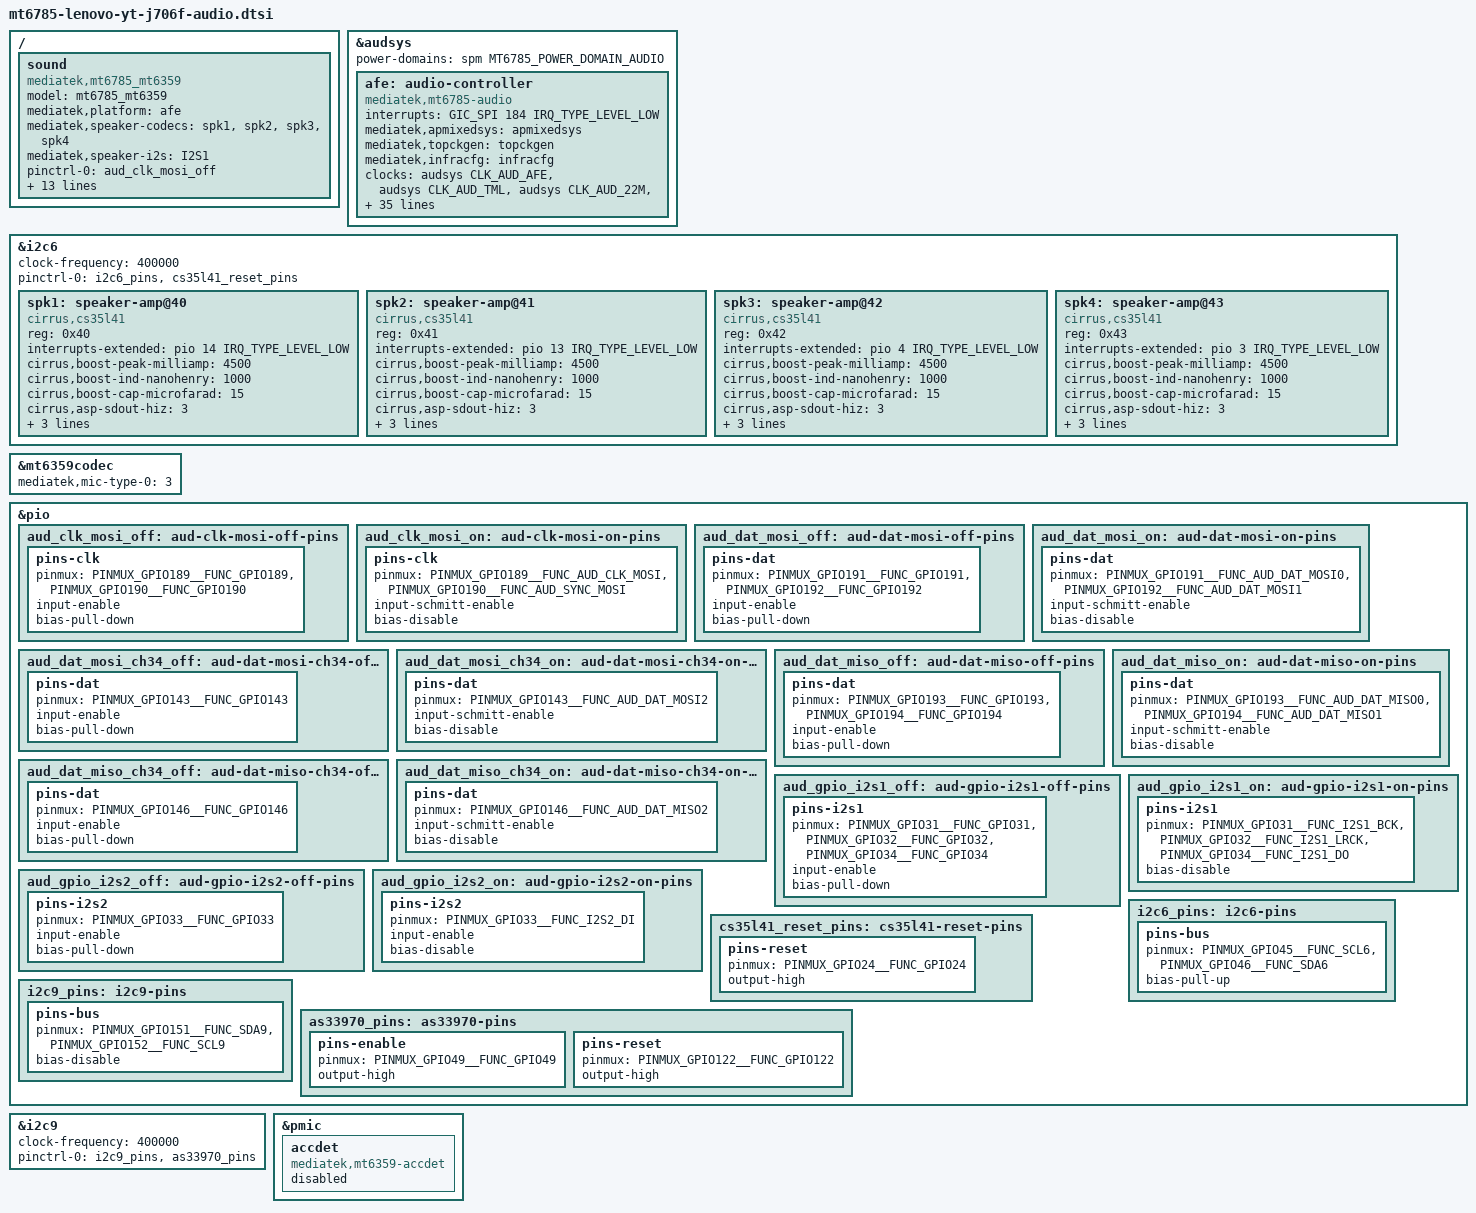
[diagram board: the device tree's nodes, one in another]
// SPDX-License-Identifier: (GPL-2.0 OR MIT)
/*
 * Audio device tree for the Lenovo Yoga Tab 11 (YT-J706F, MediaTek MT6785):
 * AFE, MT6359 PMIC codec, sound card, and 4x Cirrus Logic CS35L41
 * speaker amplifiers on i2c6.
 */

#include <dt-bindings/clock/mediatek,mt6785-clk.h>
#include <dt-bindings/interrupt-controller/arm-gic.h>
#include <dt-bindings/interrupt-controller/irq.h>
#include <dt-bindings/pinctrl/mediatek,mt6785-pinfunc.h>
#include <dt-bindings/power/mediatek,mt6785-power.h>

/*
 * AFE and its clocks adapted from Xiaomi begonia (same MT6785 SoC):
 * clock-names match aud_clks[] in mt6785-afe-clk.c (plus aud_tdm_clk for
 * mt6785-dai-tdm.c); top_i2s6..9 / apll12_div6..9 do not exist on MT6785 and
 * are treated as optional by the driver.
 */
&audsys {
	power-domains = <&spm MT6785_POWER_DOMAIN_AUDIO>;

	afe: audio-controller {
		compatible = "mediatek,mt6785-audio";
		interrupts = <GIC_SPI 184 IRQ_TYPE_LEVEL_LOW>;

		mediatek,apmixedsys = <&apmixedsys>;
		mediatek,topckgen = <&topckgen>;
		mediatek,infracfg = <&infracfg>;

		clocks = <&audsys CLK_AUD_AFE>,
			 <&audsys CLK_AUD_TML>,
			 <&audsys CLK_AUD_22M>,
			 <&audsys CLK_AUD_24M>,
			 <&audsys CLK_AUD_APLL_TUNER>,
			 <&audsys CLK_AUD_APLL2_TUNER>,
			 <&audsys CLK_AUD_TDM>,
			 <&audsys CLK_AUD_NLE>,
			 <&infracfg CLK_INFRA_AUDIO>,
			 <&infracfg CLK_INFRA_AUDIO_26M>,
			 <&topckgen CLK_TOP_AUDIO>,
			 <&topckgen CLK_TOP_AUDIO_INTBUS>,
			 <&topckgen CLK_TOP_AUDIO1>,
			 <&apmixedsys CLK_APMIXED_APLL1>,
			 <&topckgen CLK_TOP_AUDIO2>,
			 <&apmixedsys CLK_APMIXED_APLL2>,
			 <&topckgen CLK_TOP_AUDIO_ENG1>,
			 <&topckgen CLK_TOP_APLL1_D8>,
			 <&topckgen CLK_TOP_AUDIO_ENG2>,
			 <&topckgen CLK_TOP_APLL2_D8>,
			 <&topckgen CLK_TOP_AUDIO_HIRES>,
			 <&topckgen CLK_TOP_APLL_I2S0>,
			 <&topckgen CLK_TOP_APLL_I2S1>,
			 <&topckgen CLK_TOP_APLL_I2S2>,
			 <&topckgen CLK_TOP_APLL_I2S3>,
			 <&topckgen CLK_TOP_APLL_I2S4>,
			 <&topckgen CLK_TOP_APLL_I2S5>,
			 <&topckgen CLK_TOP_APLL12_DIV0>,
			 <&topckgen CLK_TOP_APLL12_DIV1>,
			 <&topckgen CLK_TOP_APLL12_DIV2>,
			 <&topckgen CLK_TOP_APLL12_DIV3>,
			 <&topckgen CLK_TOP_APLL12_DIV4>,
			 <&topckgen CLK_TOP_APLL12_DIVB>,
			 <&topckgen CLK_TOP_APLL12_DIV5>,
			 <&clk26m>,
			 /* ADDA DAPM clock supplies needed for DAC/ADC routes */
			 <&audsys CLK_AUD_DAC>,
			 <&audsys CLK_AUD_DAC_PREDIS>,
			 <&audsys CLK_AUD_3RD_DAC>,
			 <&audsys CLK_AUD_3RD_DAC_PREDIS>,
			 <&audsys CLK_AUD_ADC>,
			 <&audsys CLK_AUD_ADDA6_ADC>;
		clock-names = "aud_afe_clk",
			      "aud_tml_clk",
			      "aud_apll22m_clk",
			      "aud_apll24m_clk",
			      "aud_apll1_tuner_clk",
			      "aud_apll2_tuner_clk",
			      "aud_tdm_clk",
			      "aud_nle",
			      "aud_infra_clk",
			      "aud_infra_26m_clk",
			      "top_mux_audio",
			      "top_mux_audio_int",
			      "top_mux_aud_1",
			      "top_apll1_ck",
			      "top_mux_aud_2",
			      "top_apll2_ck",
			      "top_mux_aud_eng1",
			      "top_apll1_d8",
			      "top_mux_aud_eng2",
			      "top_apll2_d8",
			      "top_mux_audio_h",
			      "top_i2s0_m_sel",
			      "top_i2s1_m_sel",
			      "top_i2s2_m_sel",
			      "top_i2s3_m_sel",
			      "top_i2s4_m_sel",
			      "top_i2s5_m_sel",
			      "top_apll12_div0",
			      "top_apll12_div1",
			      "top_apll12_div2",
			      "top_apll12_div3",
			      "top_apll12_div4",
			      "top_apll12_divb",
			      "top_apll12_div5",
			      "top_clk26m_clk",
			      "aud_dac_clk",
			      "aud_dac_predis_clk",
			      "aud_3rd_dac_clk",
			      "aud_3rd_dac_predis_clk",
			      "aud_adc_clk",
			      "aud_adda6_adc_clk";
	};
};

/*
 * 4x Cirrus Logic CS35L41 speaker amplifiers on i2c6 (stock DT / hardware):
 * all four share active-low reset GPIO24; mainline cs35l41 requests reset-gpios
 * exclusively, so hold GPIO24 high on the bus node and let the driver soft-reset
 * each amp.
 */
&i2c6 {
	clock-frequency = <400000>;
	pinctrl-names = "default";
	pinctrl-0 = <&i2c6_pins>, <&cs35l41_reset_pins>;
	status = "okay";

	spk1: speaker-amp@40 {
		compatible = "cirrus,cs35l41";
		reg = <0x40>;
		interrupts-extended = <&pio 14 IRQ_TYPE_LEVEL_LOW>;
		cirrus,boost-peak-milliamp = <4500>;
		cirrus,boost-ind-nanohenry = <1000>;
		cirrus,boost-cap-microfarad = <15>;
		cirrus,asp-sdout-hiz = <3>;
		cirrus,gpio2-src-select = <4>;
		cirrus,gpio2-output-enable;
		#sound-dai-cells = <1>;
		sound-name-prefix = "SPK1";
	};

	spk2: speaker-amp@41 {
		compatible = "cirrus,cs35l41";
		reg = <0x41>;
		interrupts-extended = <&pio 13 IRQ_TYPE_LEVEL_LOW>;
		cirrus,boost-peak-milliamp = <4500>;
		cirrus,boost-ind-nanohenry = <1000>;
		cirrus,boost-cap-microfarad = <15>;
		cirrus,asp-sdout-hiz = <3>;
		cirrus,gpio2-src-select = <4>;
		cirrus,gpio2-output-enable;
		#sound-dai-cells = <1>;
		sound-name-prefix = "SPK2";
	};

	spk3: speaker-amp@42 {
		compatible = "cirrus,cs35l41";
		reg = <0x42>;
		interrupts-extended = <&pio 4 IRQ_TYPE_LEVEL_LOW>;
		cirrus,boost-peak-milliamp = <4500>;
		cirrus,boost-ind-nanohenry = <1000>;
		cirrus,boost-cap-microfarad = <15>;
		cirrus,asp-sdout-hiz = <3>;
		cirrus,gpio2-src-select = <4>;
		cirrus,gpio2-output-enable;
		#sound-dai-cells = <1>;
		sound-name-prefix = "SPK3";
	};

	spk4: speaker-amp@43 {
		compatible = "cirrus,cs35l41";
		reg = <0x43>;
		interrupts-extended = <&pio 3 IRQ_TYPE_LEVEL_LOW>;
		cirrus,boost-peak-milliamp = <4500>;
		cirrus,boost-ind-nanohenry = <1000>;
		cirrus,boost-cap-microfarad = <15>;
		cirrus,asp-sdout-hiz = <3>;
		cirrus,gpio2-src-select = <4>;
		cirrus,gpio2-output-enable;
		#sound-dai-cells = <1>;
		sound-name-prefix = "SPK4";
	};
};

/* MT6359 codec mic bias/type setting from begonia (DCC, avoiding preamp DC saturation) */
&mt6359codec {
	mediatek,mic-type-0 = <3>;
};

&pio {
	/* MTKAIF PMIC audio interface (begonia; state names match aud_gpios[] in mt6785-afe-gpio.c) */
	aud_clk_mosi_off: aud-clk-mosi-off-pins {
		pins-clk {
			pinmux = <PINMUX_GPIO189__FUNC_GPIO189>,
				 <PINMUX_GPIO190__FUNC_GPIO190>;
			input-enable;
			bias-pull-down;
		};
	};

	aud_clk_mosi_on: aud-clk-mosi-on-pins {
		pins-clk {
			pinmux = <PINMUX_GPIO189__FUNC_AUD_CLK_MOSI>,
				 <PINMUX_GPIO190__FUNC_AUD_SYNC_MOSI>;
			input-schmitt-enable;
			bias-disable;
		};
	};

	aud_dat_mosi_off: aud-dat-mosi-off-pins {
		pins-dat {
			pinmux = <PINMUX_GPIO191__FUNC_GPIO191>,
				 <PINMUX_GPIO192__FUNC_GPIO192>;
			input-enable;
			bias-pull-down;
		};
	};

	aud_dat_mosi_on: aud-dat-mosi-on-pins {
		pins-dat {
			pinmux = <PINMUX_GPIO191__FUNC_AUD_DAT_MOSI0>,
				 <PINMUX_GPIO192__FUNC_AUD_DAT_MOSI1>;
			input-schmitt-enable;
			bias-disable;
		};
	};

	aud_dat_mosi_ch34_off: aud-dat-mosi-ch34-off-pins {
		pins-dat {
			pinmux = <PINMUX_GPIO143__FUNC_GPIO143>;
			input-enable;
			bias-pull-down;
		};
	};

	aud_dat_mosi_ch34_on: aud-dat-mosi-ch34-on-pins {
		pins-dat {
			pinmux = <PINMUX_GPIO143__FUNC_AUD_DAT_MOSI2>;
			input-schmitt-enable;
			bias-disable;
		};
	};

	aud_dat_miso_off: aud-dat-miso-off-pins {
		pins-dat {
			pinmux = <PINMUX_GPIO193__FUNC_GPIO193>,
				 <PINMUX_GPIO194__FUNC_GPIO194>;
			input-enable;
			bias-pull-down;
		};
	};

	aud_dat_miso_on: aud-dat-miso-on-pins {
		pins-dat {
			pinmux = <PINMUX_GPIO193__FUNC_AUD_DAT_MISO0>,
				 <PINMUX_GPIO194__FUNC_AUD_DAT_MISO1>;
			input-schmitt-enable;
			bias-disable;
		};
	};

	aud_dat_miso_ch34_off: aud-dat-miso-ch34-off-pins {
		pins-dat {
			pinmux = <PINMUX_GPIO146__FUNC_GPIO146>;
			input-enable;
			bias-pull-down;
		};
	};

	aud_dat_miso_ch34_on: aud-dat-miso-ch34-on-pins {
		pins-dat {
			pinmux = <PINMUX_GPIO146__FUNC_AUD_DAT_MISO2>;
			input-schmitt-enable;
			bias-disable;
		};
	};

	/*
	 * The CS35L41 amps sit on I2S1 (output) and I2S2 (feedback input), as in
	 * the stock DT (mtk_spk_i2s_out = 1, mtk_spk_i2s_in = 2). The SMARTPA
	 * names the MediaTek reference design gives GPIO67-71 (I2S3/I2S0) do
	 * not apply to this board.
	 */
	aud_gpio_i2s1_off: aud-gpio-i2s1-off-pins {
		pins-i2s1 {
			pinmux = <PINMUX_GPIO31__FUNC_GPIO31>,
				 <PINMUX_GPIO32__FUNC_GPIO32>,
				 <PINMUX_GPIO34__FUNC_GPIO34>;
			input-enable;
			bias-pull-down;
		};
	};

	aud_gpio_i2s1_on: aud-gpio-i2s1-on-pins {
		pins-i2s1 {
			pinmux = <PINMUX_GPIO31__FUNC_I2S1_BCK>,
				 <PINMUX_GPIO32__FUNC_I2S1_LRCK>,
				 <PINMUX_GPIO34__FUNC_I2S1_DO>;
			bias-disable;
		};
	};

	aud_gpio_i2s2_off: aud-gpio-i2s2-off-pins {
		pins-i2s2 {
			pinmux = <PINMUX_GPIO33__FUNC_GPIO33>;
			input-enable;
			bias-pull-down;
		};
	};

	aud_gpio_i2s2_on: aud-gpio-i2s2-on-pins {
		pins-i2s2 {
			pinmux = <PINMUX_GPIO33__FUNC_I2S2_DI>;
			input-enable;
			bias-disable;
		};
	};

	/* I2C6 bus and shared active-low CS35L41 reset GPIO24 (stock DT / hardware) */
	i2c6_pins: i2c6-pins {
		pins-bus {
			pinmux = <PINMUX_GPIO45__FUNC_SCL6>,
				 <PINMUX_GPIO46__FUNC_SDA6>;
			bias-pull-up;
		};
	};

	cs35l41_reset_pins: cs35l41-reset-pins {
		pins-reset {
			pinmux = <PINMUX_GPIO24__FUNC_GPIO24>;
			output-high;
		};
	};

	/* I2C9 bus (GPIO151 SDA9, GPIO152 SCL9: "I2C_APPM" in the GPIO table) */
	i2c9_pins: i2c9-pins {
		pins-bus {
			pinmux = <PINMUX_GPIO151__FUNC_SDA9>,
				 <PINMUX_GPIO152__FUNC_SCL9>;
			bias-disable;
		};
	};

	/* AS33970 enable (GPIO49) and active-low reset (GPIO122), stock DT */
	as33970_pins: as33970-pins {
		pins-enable {
			pinmux = <PINMUX_GPIO49__FUNC_GPIO49>;
			output-high;
		};

		pins-reset {
			pinmux = <PINMUX_GPIO122__FUNC_GPIO122>;
			output-high;
		};
	};
};

/*
 * Synaptics AS33970 voice processor (microphones) at 0x41 on i2c9 (stock DT:
 * 1 MHz bus, enable GPIO49, reset GPIO122, interrupt GPIO12). It has no
 * firmware of its own: the host loads it through its ROM boot loader. No
 * driver yet: enable and reset are held high so a loader can reach the ROM.
 */
&i2c9 {
	clock-frequency = <400000>;
	pinctrl-names = "default";
	pinctrl-0 = <&i2c9_pins>, <&as33970_pins>;
	status = "okay";
};

/*
 * The tablet has no 3.5 mm jack: the stock DT enables the PMIC accessory
 * detection anyway (reference design), but nothing is wired to it. Keep the
 * node disabled so the MT6359 MFD skips its accdet cell, and give the sound
 * card no "Headset Jack".
 */
&pmic {
	accdet {
		compatible = "mediatek,mt6359-accdet";
		status = "disabled";
	};
};

/ {
	sound: sound {
		compatible = "mediatek,mt6785_mt6359";
		model = "mt6785_mt6359";
		mediatek,platform = <&afe>;
		mediatek,speaker-codecs = <&spk1>, <&spk2>, <&spk3>, <&spk4>;
		mediatek,speaker-i2s = "I2S1";

		pinctrl-names = "aud_clk_mosi_off", "aud_clk_mosi_on",
				"aud_dat_mosi_off", "aud_dat_mosi_on",
				"aud_dat_miso_off", "aud_dat_miso_on",
				"aud_dat_mosi_ch34_off", "aud_dat_mosi_ch34_on",
				"aud_dat_miso_ch34_off", "aud_dat_miso_ch34_on",
				"aud_gpio_i2s1_off", "aud_gpio_i2s1_on",
				"aud_gpio_i2s2_off", "aud_gpio_i2s2_on";
		pinctrl-0 = <&aud_clk_mosi_off>;
		pinctrl-1 = <&aud_clk_mosi_on>;
		pinctrl-2 = <&aud_dat_mosi_off>;
		pinctrl-3 = <&aud_dat_mosi_on>;
		pinctrl-4 = <&aud_dat_miso_off>;
		pinctrl-5 = <&aud_dat_miso_on>;
		pinctrl-6 = <&aud_dat_mosi_ch34_off>;
		pinctrl-7 = <&aud_dat_mosi_ch34_on>;
		pinctrl-8 = <&aud_dat_miso_ch34_off>;
		pinctrl-9 = <&aud_dat_miso_ch34_on>;
		pinctrl-10 = <&aud_gpio_i2s1_off>;
		pinctrl-11 = <&aud_gpio_i2s1_on>;
		pinctrl-12 = <&aud_gpio_i2s2_off>;
		pinctrl-13 = <&aud_gpio_i2s2_on>;
	};
};
